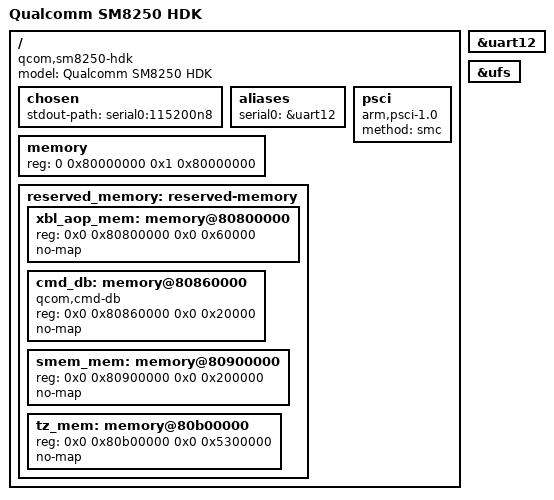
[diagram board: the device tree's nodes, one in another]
// SPDX-License-Identifier: GPL-2.0+
/*
 * Qualcomm SM8250 HDK board device tree source
 *
 * (C) Copyright 2022 Jonathan Marek <jonathan@marek.ca>
 */

/dts-v1/;

#include "sm8250.dtsi"

/ {
	model = "Qualcomm SM8250 HDK";
	compatible = "qcom,sm8250-hdk", "qcom,sm8250";
	//interrupt-parent = <&intc>;
	#address-cells = <2>;
	#size-cells = <2>;

	chosen {
		stdout-path = "serial0:115200n8";
	};

	aliases {
		serial0 = &uart12;
	};

	memory {
		device_type = "memory";
		reg = <0 0x80000000 0x1 0x80000000>;
	};

	reserved_memory: reserved-memory {
		ranges;

		#address-cells = <2>;
		#size-cells = <2>;

		/* note these 4 regions are a single range (0x80800000,0x85e00000( */

		xbl_aop_mem: memory@80800000 {
			reg = <0x0 0x80800000 0x0 0x60000>;
			no-map;
		};

		cmd_db: memory@80860000 {
			compatible = "qcom,cmd-db";
			reg = <0x0 0x80860000 0x0 0x20000>;
			no-map;
		};

		smem_mem: memory@80900000 {
			reg = <0x0 0x80900000 0x0 0x200000>;
			no-map;
		};

		tz_mem: memory@80b00000 {
			reg = <0x0 0x80b00000 0x0 0x5300000>;
			no-map;
		};
	};

	psci {
		compatible = "arm,psci-1.0";
		method = "smc";
	};
};

&uart12 {
	status = "okay";
};

&ufs {
	status = "okay";
};
